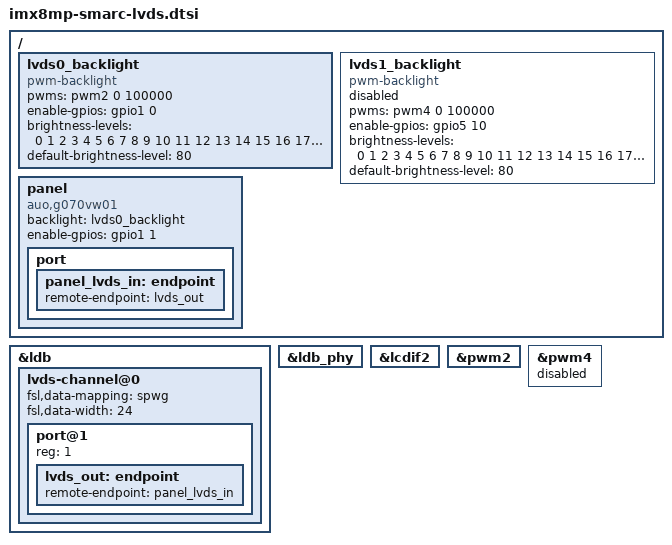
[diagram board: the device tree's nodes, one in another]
// SPDX-License-Identifier: (GPL-2.0+ OR MIT)
/*
 * Copyright 2021 Embedian, Inc.
 */

/ {
	lvds0_backlight: lvds0_backlight {
		compatible = "pwm-backlight";
		pwms = <&pwm2 0 100000>;
		enable-gpios = <&gpio1 0 0>;       /* Enable LCD0_BKLT pin */
		status = "okay";

		brightness-levels = < 0  1  2  3  4  5  6  7  8  9
				     10 11 12 13 14 15 16 17 18 19
				     20 21 22 23 24 25 26 27 28 29
				     30 31 32 33 34 35 36 37 38 39
				     40 41 42 43 44 45 46 47 48 49
				     50 51 52 53 54 55 56 57 58 59
				     60 61 62 63 64 65 66 67 68 69
				     70 71 72 73 74 75 76 77 78 79
				     80 81 82 83 84 85 86 87 88 89
				     90 91 92 93 94 95 96 97 98 99
				    100>;
		default-brightness-level = <80>;
	};

	lvds1_backlight: lvds1_backlight {
		compatible = "pwm-backlight";
		pwms = <&pwm4 0 100000>;
		enable-gpios = <&gpio5 10 0>;   /* Enable LCD1_BKLT pin */
		status = "disabled";

		brightness-levels = < 0  1  2  3  4  5  6  7  8  9
				     10 11 12 13 14 15 16 17 18 19
				     20 21 22 23 24 25 26 27 28 29
				     30 31 32 33 34 35 36 37 38 39
				     40 41 42 43 44 45 46 47 48 49
				     50 51 52 53 54 55 56 57 58 59
				     60 61 62 63 64 65 66 67 68 69
				     70 71 72 73 74 75 76 77 78 79
				     80 81 82 83 84 85 86 87 88 89
				     90 91 92 93 94 95 96 97 98 99
				    100>;
		default-brightness-level = <80>;
	};

	panel {
		compatible = "auo,g070vw01";
		backlight = <&lvds0_backlight>;
		enable-gpios = <&gpio1 1 0>;    /* Enable LCD0_VDD_EN pin */
		status = "okay";

		port {
			panel_lvds_in: endpoint {
			remote-endpoint = <&lvds_out>;
			};
		};
	};
};

&ldb {
        status = "okay";

        lvds-channel@0 {
		fsl,data-mapping = "spwg";
                fsl,data-width = <24>;
                status = "okay";

                port@1 {
                        reg = <1>;

                        lvds_out: endpoint {
                                remote-endpoint = <&panel_lvds_in>;
                        };
                };
        };
};

&ldb_phy {
	status = "okay";
};

&lcdif2 {
	status = "okay";
};

&pwm2 {
	status = "okay";
};

&pwm4 {
	status = "disabled";
};
